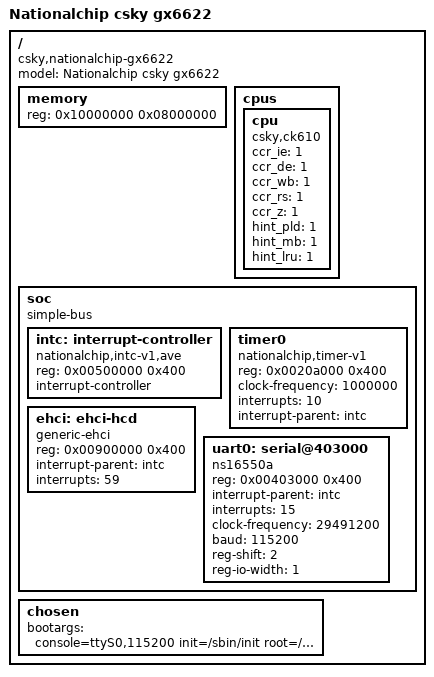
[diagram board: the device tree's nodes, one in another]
/dts-v1/;
/ {
	model = "Nationalchip csky gx6622";
	compatible = "csky,nationalchip-gx6622";
	#address-cells = <1>;
	#size-cells = <1>;

	memory {
		device_type = "memory";
		reg = <0x10000000 0x08000000>;
	};

	cpus {
		#address-cells = <0>;
		#size-cells = <0>;

		cpu {
			compatible = "csky,ck610";
			device_type = "cpu";
			ccr_ie   = <1>;
			ccr_de   = <1>;
			ccr_wb   = <1>;
			ccr_rs   = <1>;
			ccr_z    = <1>;
			hint_pld = <1>;
			hint_mb  = <1>;
			hint_lru = <1>;
		};
	};

	soc {
		#address-cells = <1>;
		#size-cells = <1>;
		compatible = "simple-bus";
		ranges;

		intc: interrupt-controller {
			compatible = "nationalchip,intc-v1,ave";
			reg = <0x00500000 0x400>;
			interrupt-controller;
			#interrupt-cells = <1>;
		};

		timer0 {
			compatible = "nationalchip,timer-v1";
			reg = <0x0020a000 0x400>;
			clock-frequency = <1000000>;
			interrupts = <10>;
			interrupt-parent = <&intc>;
		};

		ehci: ehci-hcd {
			compatible = "generic-ehci";
			reg = <0x00900000 0x400>;
			interrupt-parent = <&intc>;
			interrupts = <59>;
		};

		uart0: serial@403000 {
			compatible = "ns16550a";
			reg = <0x00403000 0x400>;
			interrupt-parent = <&intc>;
			interrupts = <15>;
			clock-frequency = <29491200>;
			baud = <115200>;
			reg-shift = <2>;
			reg-io-width = <1>;
		};
	};

	chosen {
		bootargs = "console=ttyS0,115200 init=/sbin/init root=/dev/sda2 rw rootwait";
	};
};
